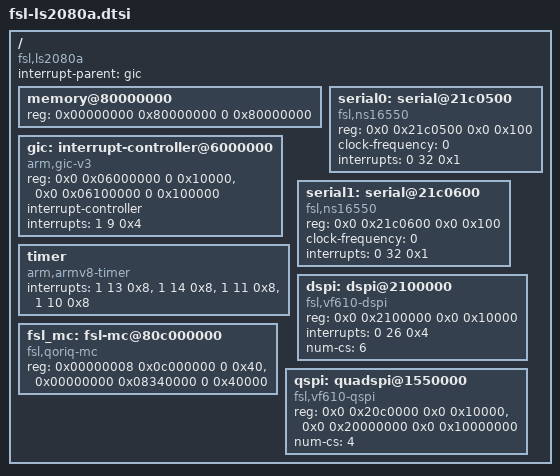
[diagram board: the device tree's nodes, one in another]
/*
 * Freescale ls2080a SOC common device tree source
 *
 * Copyright 2013-2015 Freescale Semiconductor, Inc.
 *
 * SPDX-License-Identifier:	GPL-2.0+
 */

/ {
	compatible = "fsl,ls2080a";
	interrupt-parent = <&gic>;
	#address-cells = <2>;
	#size-cells = <2>;

	memory@80000000 {
		device_type = "memory";
		reg = <0x00000000 0x80000000 0 0x80000000>;
		      /* DRAM space - 1, size : 2 GB DRAM */
	};

	gic: interrupt-controller@6000000 {
		compatible = "arm,gic-v3";
		reg = <0x0 0x06000000 0 0x10000>, /* GIC Dist */
		      <0x0 0x06100000 0 0x100000>; /* GICR (RD_base + SGI_base) */
		#interrupt-cells = <3>;
		interrupt-controller;
		interrupts = <1 9 0x4>;
	};

	timer {
		compatible = "arm,armv8-timer";
		interrupts = <1 13 0x8>, /* Physical Secure PPI, active-low */
			     <1 14 0x8>, /* Physical Non-Secure PPI, active-low */
			     <1 11 0x8>, /* Virtual PPI, active-low */
			     <1 10 0x8>; /* Hypervisor PPI, active-low */
	};

	serial0: serial@21c0500 {
		device_type = "serial";
		compatible = "fsl,ns16550", "ns16550a";
		reg = <0x0 0x21c0500 0x0 0x100>;
		clock-frequency = <0>;	/* Updated by bootloader */
		interrupts = <0 32 0x1>; /* edge triggered */
	};

	serial1: serial@21c0600 {
		device_type = "serial";
		compatible = "fsl,ns16550", "ns16550a";
		reg = <0x0 0x21c0600 0x0 0x100>;
		clock-frequency = <0>; 	/* Updated by bootloader */
		interrupts = <0 32 0x1>; /* edge triggered */
	};

	fsl_mc: fsl-mc@80c000000 {
		compatible = "fsl,qoriq-mc";
		reg = <0x00000008 0x0c000000 0 0x40>,	 /* MC portal base */
		      <0x00000000 0x08340000 0 0x40000>; /* MC control reg */
	};

	dspi: dspi@2100000 {
		compatible = "fsl,vf610-dspi";
		#address-cells = <1>;
		#size-cells = <0>;
		reg = <0x0 0x2100000 0x0 0x10000>;
		interrupts = <0 26 0x4>; /* Level high type */
		num-cs = <6>;
	};

	qspi: quadspi@1550000 {
		compatible = "fsl,vf610-qspi";
		#address-cells = <1>;
		#size-cells = <0>;
		reg = <0x0 0x20c0000 0x0 0x10000>,
			<0x0 0x20000000 0x0 0x10000000>;
		reg-names = "QuadSPI", "QuadSPI-memory";
		num-cs = <4>;
	};
};
